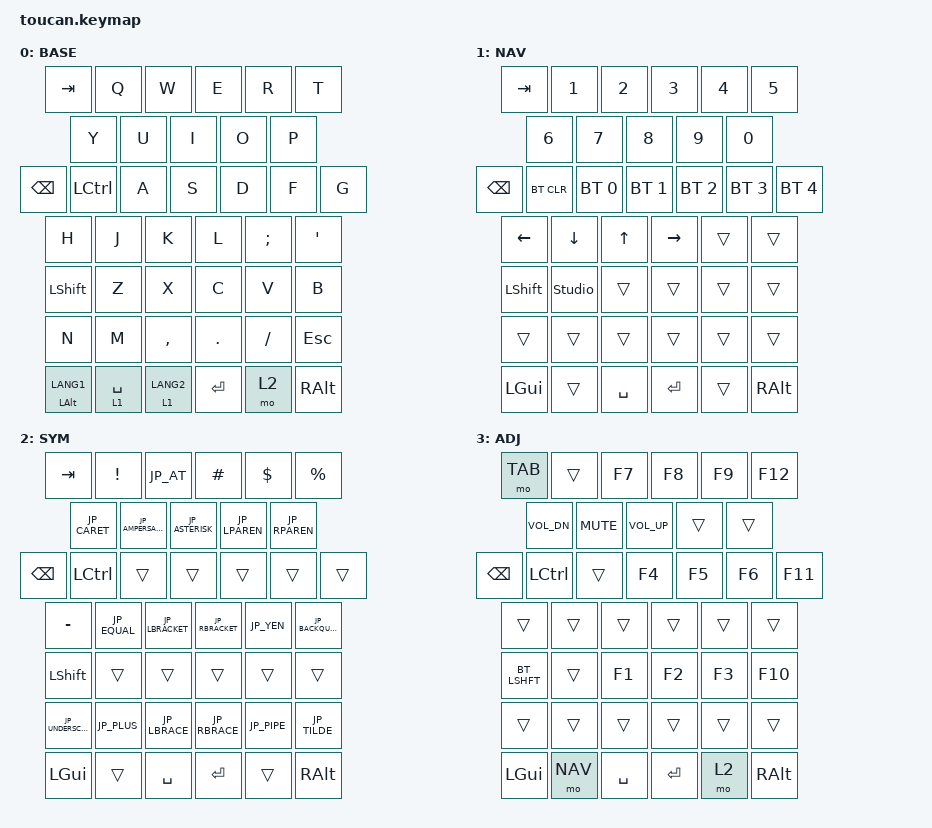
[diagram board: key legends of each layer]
#include <behaviors.dtsi>
#include <dt-bindings/zmk/bt.h>
#include <dt-bindings/zmk/keys.h>

// OS設定を日本語キーボードのまま使用するための変換定義

#define JP_DQUOTE       AT                // "
#define JP_AMPERSAND    CARET             // &
#define JP_QUOTE        AMPERSAND         // '
#define JP_EQUAL        UNDER             // =
#define JP_CARET        EQUAL             // ^
#define JP_YEN          0x89              // ¥
#define JP_PLUS         COLON             // +
#define JP_TILDE        PLUS              // ~
#define JP_PIPE         LS(0x89)          // |
#define JP_AT           LEFT_BRACKET      // @
#define JP_COLON        SINGLE_QUOTE      // :
#define JP_ASTERISK     DOUBLE_QUOTES     // *
#define JP_BACKQUOTE    LEFT_BRACE        // `
#define JP_UNDERSCORE   LS(0x87)          // _
#define JP_LBRACKET     RIGHT_BRACKET     // [
#define JP_RBRACKET     BACKSLASH         // ]
#define JP_LPAREN       ASTERISK          // (
#define JP_RPAREN       LEFT_PARENTHESIS  // )
#define JP_LBRACE       RIGHT_BRACE       // {
#define JP_RBRACE       PIPE              // }
#define JP_KANA         LANGUAGE_1        // かな
#define JP_EISU         LANGUAGE_2        // 英数
#define JP_HANZEN       GRAVE             // 半角/全角
#define BASE 0
#define NAV  1
#define SYM  2
#define ADJ  3

/ {
    conditional_layers {
        compatible = "zmk,conditional-layers";

        tri_layer {
            if-layers = <1 2>;
            then-layer = <3>;
        };
    };

    macros {
        macro_1: macro_1 {
            compatible = "zmk,behavior-macro";
            #binding-cells = <0>;
            bindings = <&none>;
            label = "MACRO_1";
        };
    };

    behaviors {
        hold_top_1: hold_top_1 {
            compatible = "zmk,behavior-hold-tap";
            label = "HOLD_TOP_1";
            bindings = <&mo>, <&kp>;

            #binding-cells = <2>;
            tapping-term-ms = <200>;
            flavor = "balanced";
        };
    };

    combos {
        compatible = "zmk,combos";

        Combos_1 {
            bindings = <&kp JP_AT>;
            key-positions = <25 26>;
        };

        Combos_2 {
            bindings = <&kp UNDERSCORE>;
            key-positions = <21 22>;
        };

        Combos_3 {
            bindings = <&kp EXCLAMATION>;
            key-positions = <16 15>;
        };

        Combos_4 {
            bindings = <&kp QUESTION>;
            key-positions = <19 20>;
        };

        Combos_5 {
            bindings = <&kp MINUS>;
            key-positions = <22 23>;
        };
    };

    keymap {
        compatible = "zmk,keymap";

        base {
            display-name = "BASE";
            bindings = <
&kp TAB  &kp Q  &kp W  &kp E  &kp R  &kp T  &kp Y  &kp U  &kp I  &kp O  &kp P  &kp BSPC  &kp LCTRL  &kp A  &kp S  &kp D  &kp F  &kp G  &kp H  &kp J  &kp K  &kp L  &kp SEMI  &kp SQT  &kp LSHFT  &kp Z  &kp X  &kp C  &kp V  &kp B  &kp N  &kp M  &kp COMMA  &kp DOT  &kp FSLH  &kp ESC  &mt LEFT_ALT LANG1  &hold_top_1 1 SPACE  &hold_top_1 1 LANG2  &kp RET  &mo 2  &kp RALT
            >;
        };

        nav {
            display-name = "NAV";
            bindings = <
&kp TAB  &kp N1  &kp N2  &kp N3  &kp N4  &kp N5  &kp N6  &kp N7  &kp N8  &kp N9  &kp N0  &kp BSPC  &bt BT_CLR  &bt BT_SEL 0  &bt BT_SEL 1  &bt BT_SEL 2  &bt BT_SEL 3  &bt BT_SEL 4  &kp LEFT  &kp DOWN  &kp UP  &kp RIGHT  &trans  &trans  &kp LSHFT  &studio_unlock  &trans  &trans  &trans  &trans  &trans  &trans  &trans  &trans  &trans  &trans  &kp LGUI  &trans  &kp SPACE  &kp RET  &trans  &kp RALT
            >;
        };

        sym {
            display-name = "SYM";
            bindings = <
&kp TAB  &kp EXCL  &kp JP_AT  &kp HASH  &kp DLLR  &kp PRCNT  
&kp JP_CARET  &kp JP_AMPERSAND  &kp JP_ASTERISK  &kp JP_LPAREN &kp JP_RPAREN  
&kp BSPC  &kp LCTRL  &trans  &trans  &trans  &trans  &trans  
&kp MINUS  &kp JP_EQUAL  &kp JP_LBRACKET  &kp JP_RBRACKET  &kp JP_YEN  &kp JP_BACKQUOTE
&kp LSHFT  &trans  &trans  &trans  &trans  &trans  
&kp JP_UNDERSCORE  &kp JP_PLUS  &kp JP_LBRACE  &kp JP_RBRACE  &kp JP_PIPE  &kp JP_TILDE  
&kp LGUI  &trans  &kp SPACE  &kp RET  &trans  &kp RALT
            >;
        };

        adj {
            display-name = "ADJ";
            bindings = <
&mo TAB  &trans  &kp F7  &kp F8  &kp F9  &kp F12  &kp C_VOL_DN  &kp C_MUTE  &kp C_VOL_UP  &trans  &trans  &kp BSPC  &kp LCTRL  &trans  &kp F4  &kp F5  &kp F6  &kp F11  &trans  &trans  &trans  &trans  &trans  &trans  &bt LSHFT  &trans  &kp F1  &kp F2  &kp F3  &kp F10  &trans  &trans  &trans  &trans  &trans  &trans  &kp LGUI  &mo NAV  &kp SPACE  &kp RET  &mo 2  &kp RALT
            >;
        };

        extra_1 { status = "reserved"; };

        extra_2 { status = "reserved"; };

        extra_3 { status = "reserved"; };
    };
};
